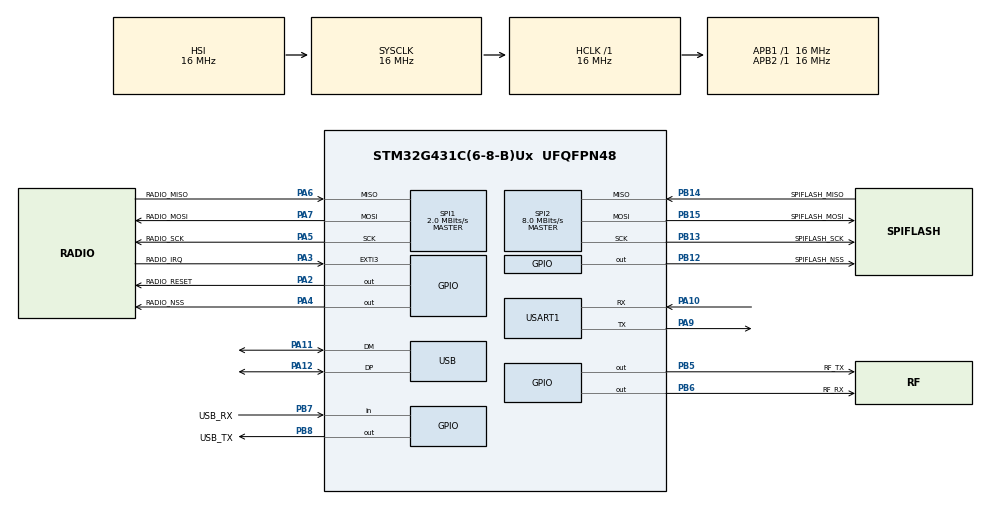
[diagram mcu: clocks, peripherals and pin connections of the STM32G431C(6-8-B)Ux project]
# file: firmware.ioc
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Mcu.Family=STM32G4
Mcu.Name=STM32G431C(6-8-B)Ux
Mcu.Package=UFQFPN48
NVIC.EXTI3_IRQn=true\:0\:0\:false\:false\:true\:true\:true\:true
NVIC.PriorityGroup=NVIC_PRIORITYGROUP_4
NVIC.USB_LP_IRQn=true\:0\:0\:false\:false\:true\:false\:true\:true
PA10.Mode=Asynchronous
PA10.Signal=USART1_RX
PA11.Mode=Device
PA11.Signal=USB_DM
PA12.Mode=Device
PA12.Signal=USB_DP
PA13.Mode=JTAG_5_pins
PA13.Signal=SYS_JTMS-SWDIO
PA14.Mode=JTAG_5_pins
PA14.Signal=SYS_JTCK-SWCLK
PA15.Mode=JTAG_5_pins
PA15.Signal=SYS_JTDI
PA2.GPIO_Label=RADIO_RESET
PA2.Signal=GPIO_Output
PA3.GPIO_Label=RADIO_IRQ
PA3.Signal=GPXTI3
PA4.GPIO_Label=RADIO_NSS
PA4.Signal=GPIO_Output
PA5.GPIO_Label=RADIO_SCK
PA5.Mode=Full_Duplex_Master
PA5.Signal=SPI1_SCK
PA6.GPIO_Label=RADIO_MISO
PA6.Mode=Full_Duplex_Master
PA6.Signal=SPI1_MISO
PA7.GPIO_Label=RADIO_MOSI
PA7.Mode=Full_Duplex_Master
PA7.Signal=SPI1_MOSI
PA9.Mode=Asynchronous
PA9.Signal=USART1_TX
PB12.GPIO_Label=SPIFLASH_NSS
PB12.Signal=GPIO_Output
PB13.GPIO_Label=SPIFLASH_SCK
PB13.Mode=Full_Duplex_Master
PB13.Signal=SPI2_SCK
PB14.GPIO_Label=SPIFLASH_MISO
PB14.Mode=Full_Duplex_Master
PB14.Signal=SPI2_MISO
PB15.GPIO_Label=SPIFLASH_MOSI
PB15.Mode=Full_Duplex_Master
PB15.Signal=SPI2_MOSI
PB3.Mode=JTAG_5_pins
PB3.Signal=SYS_JTDO-SWO
PB4.Mode=JTAG_5_pins
PB4.Signal=SYS_JTRST
PB5.GPIO_Label=RF_TX
PB5.Signal=GPIO_Output
PB6.GPIO_Label=RF_RX
PB6.Signal=GPIO_Output
PB7.GPIO_Label=USB_RX
PB7.Signal=GPIO_Input
PB8-BOOT0.GPIO_Label=USB_TX
PB8-BOOT0.Signal=GPIO_Output
PF0-OSC_IN.Mode=HSE-External-Oscillator
PF0-OSC_IN.Signal=RCC_OSC_IN
PF1-OSC_OUT.Mode=HSE-External-Oscillator
PF1-OSC_OUT.Signal=RCC_OSC_OUT
ProjectManager.HeapSize=0x200
ProjectManager.StackSize=0x400
ProjectManager.TargetToolchain=Makefile
RCC.AHBFreq_Value=16000000
RCC.APB1Freq_Value=16000000
RCC.APB1TimFreq_Value=16000000
RCC.APB2Freq_Value=16000000
RCC.APB2TimFreq_Value=16000000
RCC.CortexFreq_Value=16000000
RCC.EXTERNAL_CLOCK_VALUE=12288000
RCC.HCLKFreq_Value=16000000
RCC.HSE_VALUE=32000000
RCC.HSI48_VALUE=48000000
RCC.HSI_VALUE=16000000
RCC.LSE_VALUE=32768
RCC.PLLN=12
RCC.PLLQ=RCC_PLLQ_DIV4
RCC.SYSCLKFreq_VALUE=16000000
RCC.USBFreq_Value=48000000
RCC.VCOOutputFreq_Value=192000000
SPI1.BaudRatePrescaler=SPI_BAUDRATEPRESCALER_8
SPI1.CalculateBaudRate=2.0 MBits/s
SPI1.DataSize=SPI_DATASIZE_8BIT
SPI1.Direction=SPI_DIRECTION_2LINES
SPI1.Mode=SPI_MODE_MASTER
SPI1.VirtualType=VM_MASTER
SPI2.CalculateBaudRate=8.0 MBits/s
SPI2.Direction=SPI_DIRECTION_2LINES
SPI2.Mode=SPI_MODE_MASTER
SPI2.VirtualType=VM_MASTER
USART1.VirtualMode-Asynchronous=VM_ASYNC
USB_DEVICE.CLASS_NAME_FS=CDC
USB_DEVICE.VirtualMode=Cdc
USB_DEVICE.VirtualModeFS=Cdc_FS
VP_SYS_VS_DBSignals.Mode=DisableDeadBatterySignals
VP_USB_DEVICE_VS_USB_DEVICE_CDC_FS.Mode=CDC_FS
board=custom

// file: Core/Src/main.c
/* USER CODE BEGIN Header */
/**
  ******************************************************************************
  * @file           : main.c
  * @brief          : Main program body
  ******************************************************************************
  * @attention
  *
  * Copyright (c) 2023 STMicroelectronics.
  * All rights reserved.
  *
  * This software is licensed under terms that can be found in the LICENSE file
  * in the root directory of this software component.
  * If no LICENSE file comes with this software, it is provided AS-IS.
  *
  ******************************************************************************
  */
/* USER CODE END Header */
#include "main.h"
#include "usb_device.h"

/* USER CODE BEGIN Includes */

#include <errno.h>
#include <sys/unistd.h> // STDOUT_FILENO, STDERR_FILENO
#include <stdio.h>

#include "entry.h"

/* USER CODE END Includes */

SPI_HandleTypeDef hspi1;
SPI_HandleTypeDef hspi2;

UART_HandleTypeDef huart1;

void SystemClock_Config(void);
static void MX_GPIO_Init(void);
static void MX_SPI1_Init(void);
static void MX_SPI2_Init(void);
static void MX_USART1_UART_Init(void);

/* USER CODE BEGIN 0 */

int _write(int file, char *data, int len)
{
  if ((file != STDOUT_FILENO) && (file != STDERR_FILENO))
  {
    errno = EBADF;
    return -1;
  }

  // arbitrary timeout 1000
  HAL_StatusTypeDef status = HAL_UART_Transmit(&huart1, (uint8_t*)data, len, 1000);
  CDC_Transmit_FS((uint8_t*)data, len);

  // return # of bytes written - as best we can tell
  return (status == HAL_OK ? len : 0);
}

/* USER CODE END 0 */

int main(void)
{

  /* MCU Configuration--------------------------------------------------------*/

  /* Reset of all peripherals, Initializes the Flash interface and the Systick. */
  HAL_Init();

  /* Configure the system clock */
  SystemClock_Config();

  /* Initialize all configured peripherals */
  MX_GPIO_Init();
  MX_SPI1_Init();
  MX_SPI2_Init();
  MX_USART1_UART_Init();
  MX_USB_Device_Init();
  /* USER CODE BEGIN 2 */
  entry();

  /* USER CODE END 2 */

  /* Infinite loop */
  while (1)
  {

  }
}

void SystemClock_Config(void)
{
  RCC_OscInitTypeDef RCC_OscInitStruct = {0};
  RCC_ClkInitTypeDef RCC_ClkInitStruct = {0};

  /** Configure the main internal regulator output voltage
  */
  HAL_PWREx_ControlVoltageScaling(PWR_REGULATOR_VOLTAGE_SCALE1);

  /** Initializes the RCC Oscillators according to the specified parameters
  * in the RCC_OscInitTypeDef structure.
  */
  RCC_OscInitStruct.OscillatorType = RCC_OSCILLATORTYPE_HSI;
  RCC_OscInitStruct.HSIState = RCC_HSI_ON;
  RCC_OscInitStruct.HSICalibrationValue = RCC_HSICALIBRATION_DEFAULT;
  RCC_OscInitStruct.PLL.PLLState = RCC_PLL_ON;
  RCC_OscInitStruct.PLL.PLLSource = RCC_PLLSOURCE_HSI;
  RCC_OscInitStruct.PLL.PLLM = RCC_PLLM_DIV1;
  RCC_OscInitStruct.PLL.PLLN = 12;
  RCC_OscInitStruct.PLL.PLLP = RCC_PLLP_DIV2;
  RCC_OscInitStruct.PLL.PLLQ = RCC_PLLQ_DIV4;
  RCC_OscInitStruct.PLL.PLLR = RCC_PLLR_DIV2;
  if (HAL_RCC_OscConfig(&RCC_OscInitStruct) != HAL_OK)
  {
    Error_Handler();
  }

  /** Initializes the CPU, AHB and APB buses clocks
  */
  RCC_ClkInitStruct.ClockType = RCC_CLOCKTYPE_HCLK|RCC_CLOCKTYPE_SYSCLK
                              |RCC_CLOCKTYPE_PCLK1|RCC_CLOCKTYPE_PCLK2;
  RCC_ClkInitStruct.SYSCLKSource = RCC_SYSCLKSOURCE_HSI;
  RCC_ClkInitStruct.AHBCLKDivider = RCC_SYSCLK_DIV1;
  RCC_ClkInitStruct.APB1CLKDivider = RCC_HCLK_DIV1;
  RCC_ClkInitStruct.APB2CLKDivider = RCC_HCLK_DIV1;

  if (HAL_RCC_ClockConfig(&RCC_ClkInitStruct, FLASH_LATENCY_0) != HAL_OK)
  {
    Error_Handler();
  }
}

static void MX_SPI1_Init(void)
{

  /* SPI1 parameter configuration*/
  hspi1.Instance = SPI1;
  hspi1.Init.Mode = SPI_MODE_MASTER;
  hspi1.Init.Direction = SPI_DIRECTION_2LINES;
  hspi1.Init.DataSize = SPI_DATASIZE_8BIT;
  hspi1.Init.CLKPolarity = SPI_POLARITY_LOW;
  hspi1.Init.CLKPhase = SPI_PHASE_1EDGE;
  hspi1.Init.NSS = SPI_NSS_SOFT;
  hspi1.Init.BaudRatePrescaler = SPI_BAUDRATEPRESCALER_8;
  hspi1.Init.FirstBit = SPI_FIRSTBIT_MSB;
  hspi1.Init.TIMode = SPI_TIMODE_DISABLE;
  hspi1.Init.CRCCalculation = SPI_CRCCALCULATION_DISABLE;
  hspi1.Init.CRCPolynomial = 7;
  hspi1.Init.CRCLength = SPI_CRC_LENGTH_DATASIZE;
  hspi1.Init.NSSPMode = SPI_NSS_PULSE_ENABLE;
  if (HAL_SPI_Init(&hspi1) != HAL_OK)
  {
    Error_Handler();
  }

}

static void MX_SPI2_Init(void)
{

  /* SPI2 parameter configuration*/
  hspi2.Instance = SPI2;
  hspi2.Init.Mode = SPI_MODE_MASTER;
  hspi2.Init.Direction = SPI_DIRECTION_2LINES;
  hspi2.Init.DataSize = SPI_DATASIZE_4BIT;
  hspi2.Init.CLKPolarity = SPI_POLARITY_LOW;
  hspi2.Init.CLKPhase = SPI_PHASE_1EDGE;
  hspi2.Init.NSS = SPI_NSS_SOFT;
  hspi2.Init.BaudRatePrescaler = SPI_BAUDRATEPRESCALER_2;
  hspi2.Init.FirstBit = SPI_FIRSTBIT_MSB;
  hspi2.Init.TIMode = SPI_TIMODE_DISABLE;
  hspi2.Init.CRCCalculation = SPI_CRCCALCULATION_DISABLE;
  hspi2.Init.CRCPolynomial = 7;
  hspi2.Init.CRCLength = SPI_CRC_LENGTH_DATASIZE;
  hspi2.Init.NSSPMode = SPI_NSS_PULSE_ENABLE;
  if (HAL_SPI_Init(&hspi2) != HAL_OK)
  {
    Error_Handler();
  }

}

static void MX_USART1_UART_Init(void)
{

  huart1.Instance = USART1;
  huart1.Init.BaudRate = 115200;
  huart1.Init.WordLength = UART_WORDLENGTH_8B;
  huart1.Init.StopBits = UART_STOPBITS_1;
  huart1.Init.Parity = UART_PARITY_NONE;
  huart1.Init.Mode = UART_MODE_TX_RX;
  huart1.Init.HwFlowCtl = UART_HWCONTROL_NONE;
  huart1.Init.OverSampling = UART_OVERSAMPLING_16;
  huart1.Init.OneBitSampling = UART_ONE_BIT_SAMPLE_DISABLE;
  huart1.Init.ClockPrescaler = UART_PRESCALER_DIV1;
  huart1.AdvancedInit.AdvFeatureInit = UART_ADVFEATURE_NO_INIT;
  if (HAL_UART_Init(&huart1) != HAL_OK)
  {
    Error_Handler();
  }
  if (HAL_UARTEx_SetTxFifoThreshold(&huart1, UART_TXFIFO_THRESHOLD_1_8) != HAL_OK)
  {
    Error_Handler();
  }
  if (HAL_UARTEx_SetRxFifoThreshold(&huart1, UART_RXFIFO_THRESHOLD_1_8) != HAL_OK)
  {
    Error_Handler();
  }
  if (HAL_UARTEx_DisableFifoMode(&huart1) != HAL_OK)
  {
    Error_Handler();
  }

}

static void MX_GPIO_Init(void)
{
  GPIO_InitTypeDef GPIO_InitStruct = {0};

  /* GPIO Ports Clock Enable */
  __HAL_RCC_GPIOF_CLK_ENABLE();
  __HAL_RCC_GPIOA_CLK_ENABLE();
  __HAL_RCC_GPIOB_CLK_ENABLE();

  /*Configure GPIO pin Output Level */
  HAL_GPIO_WritePin(GPIOA, RADIO_RESET_Pin|RADIO_NSS_Pin, GPIO_PIN_RESET);

  /*Configure GPIO pin Output Level */
  HAL_GPIO_WritePin(GPIOB, SPIFLASH_NSS_Pin|RF_TX_Pin|RF_RX_Pin|USB_TX_Pin, GPIO_PIN_RESET);

  /*Configure GPIO pins : RADIO_RESET_Pin RADIO_NSS_Pin */
  GPIO_InitStruct.Pin = RADIO_RESET_Pin|RADIO_NSS_Pin;
  GPIO_InitStruct.Mode = GPIO_MODE_OUTPUT_PP;
  GPIO_InitStruct.Pull = GPIO_NOPULL;
  GPIO_InitStruct.Speed = GPIO_SPEED_FREQ_LOW;
  HAL_GPIO_Init(GPIOA, &GPIO_InitStruct);

  /*Configure GPIO pin : RADIO_IRQ_Pin */
  GPIO_InitStruct.Pin = RADIO_IRQ_Pin;
  GPIO_InitStruct.Mode = GPIO_MODE_IT_RISING;
  GPIO_InitStruct.Pull = GPIO_NOPULL;
  HAL_GPIO_Init(RADIO_IRQ_GPIO_Port, &GPIO_InitStruct);

  /*Configure GPIO pins : SPIFLASH_NSS_Pin RF_TX_Pin RF_RX_Pin USB_TX_Pin */
  GPIO_InitStruct.Pin = SPIFLASH_NSS_Pin|RF_TX_Pin|RF_RX_Pin|USB_TX_Pin;
  GPIO_InitStruct.Mode = GPIO_MODE_OUTPUT_PP;
  GPIO_InitStruct.Pull = GPIO_NOPULL;
  GPIO_InitStruct.Speed = GPIO_SPEED_FREQ_LOW;
  HAL_GPIO_Init(GPIOB, &GPIO_InitStruct);

  /*Configure GPIO pin : USB_RX_Pin */
  GPIO_InitStruct.Pin = USB_RX_Pin;
  GPIO_InitStruct.Mode = GPIO_MODE_INPUT;
  GPIO_InitStruct.Pull = GPIO_NOPULL;
  HAL_GPIO_Init(USB_RX_GPIO_Port, &GPIO_InitStruct);

  /* EXTI interrupt init*/
  HAL_NVIC_SetPriority(EXTI3_IRQn, 0, 0);
  HAL_NVIC_EnableIRQ(EXTI3_IRQn);

}

void Error_Handler(void)
{
  __disable_irq();
  while (1)
  {
  }
}
